# AST1080 register map
File version: 1.0
CPU: CM4 r0p1, little endian, MPU, FPU, 4 interrupt priority bits, 256 interrupts
Registers are 32-bit, read-write, reset 0x0 unless marked. A register's access mark holds for its fields unless they carry their own. Offsets are from the block's base; [hi:lo] are bit positions; {n}, {i} and the like mark numbered series.

## scu (part 2 of 2)
Base 0x74C02000
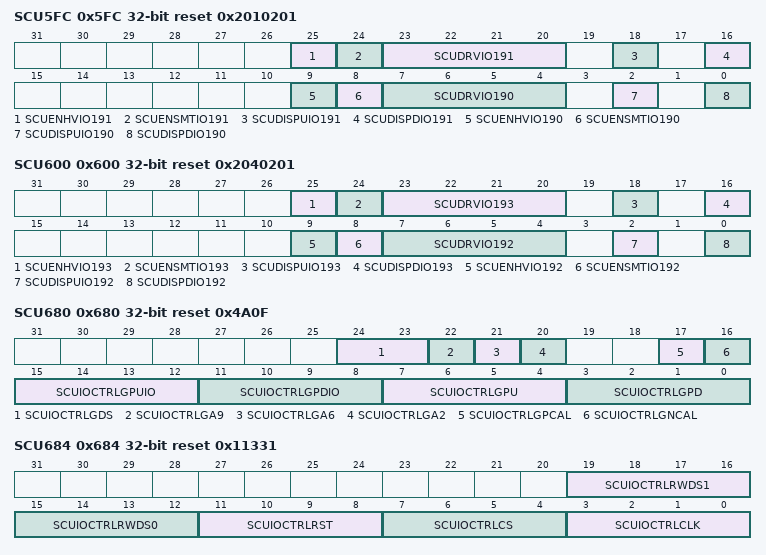
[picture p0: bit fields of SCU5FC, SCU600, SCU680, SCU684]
0x5FC SCU5FC reset 0x2010201 — IO Control \#96
  [25] SCUENHVIO191, [24] SCUENSMTIO191, [23:20] SCUDRVIO191, [18] SCUDISPUIO191, [16] SCUDISPDIO191, [9] SCUENHVIO190, [8] SCUENSMTIO190, [7:4] SCUDRVIO190, [2] SCUDISPUIO190, [0] SCUDISPDIO190
0x600 SCU600 reset 0x2040201 — IO Control \#97
  [25] SCUENHVIO193, [24] SCUENSMTIO193, [23:20] SCUDRVIO193, [18] SCUDISPUIO193, [16] SCUDISPDIO193, [9] SCUENHVIO192, [8] SCUENSMTIO192, [7:4] SCUDRVIO192, [2] SCUDISPUIO192, [0] SCUDISPDIO192
0x680 SCU680 reset 0x4A0F — IO Control 0 Regiser
  [24:23] SCUIOCTRLGDS, [22] SCUIOCTRLGA9, [21] SCUIOCTRLGA6, [20] SCUIOCTRLGA2, [17] SCUIOCTRLGPCAL, [16] SCUIOCTRLGNCAL, [15:12] SCUIOCTRLGPUIO, [11:8] SCUIOCTRLGPDIO, [7:4] SCUIOCTRLGPU, [3:0] SCUIOCTRLGPD
0x684 SCU684 reset 0x11331 — HRAM IO Control 1 Register
  [19:16] SCUIOCTRLRWDS1, [15:12] SCUIOCTRLRWDS0, [11:8] SCUIOCTRLRST, [7:4] SCUIOCTRLCS, [3:0] SCUIOCTRLCLK
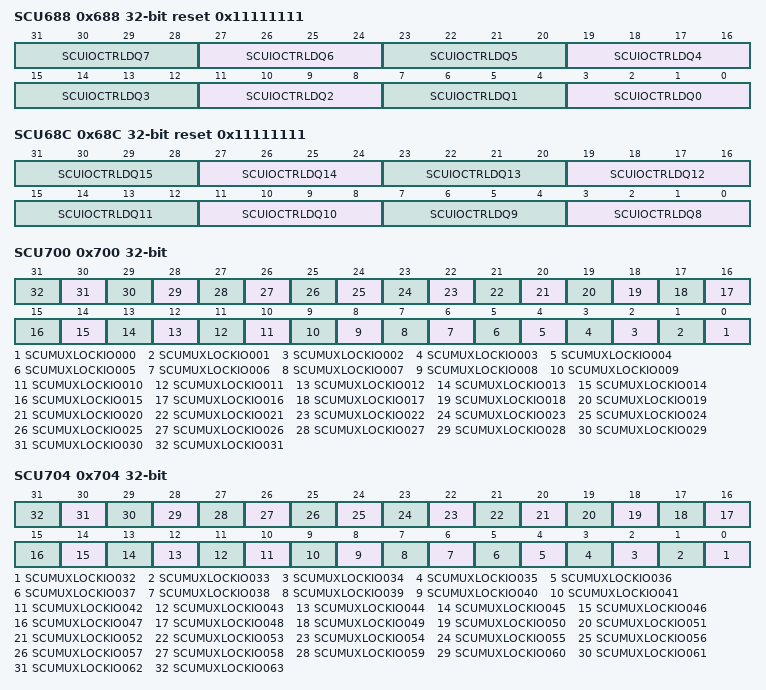
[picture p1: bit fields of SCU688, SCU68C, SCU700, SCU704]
0x688 SCU688 reset 0x11111111 — HRAM IO Control 2 Register
  [4n+3:4n] SCUIOCTRLDQ{n} (n=0..7)
0x68C SCU68C reset 0x11111111 — HRAM IO Control 3 Register
  [4n-29:4n-32] SCUIOCTRLDQ{n} (n=8..15)
0x6FC SCU6FC — GPIO Passthrough Debounce Register
  [3:0] SCUENGPIOPTDEB
0x700 SCU700 — IO Lock 1 Register 1
  [n] SCUMUXLOCKIO{n:03} (n=0..31)
0x704 SCU704 — IO Lock Register 2
  [n-32] SCUMUXLOCKIO{n:03} (n=32..63)
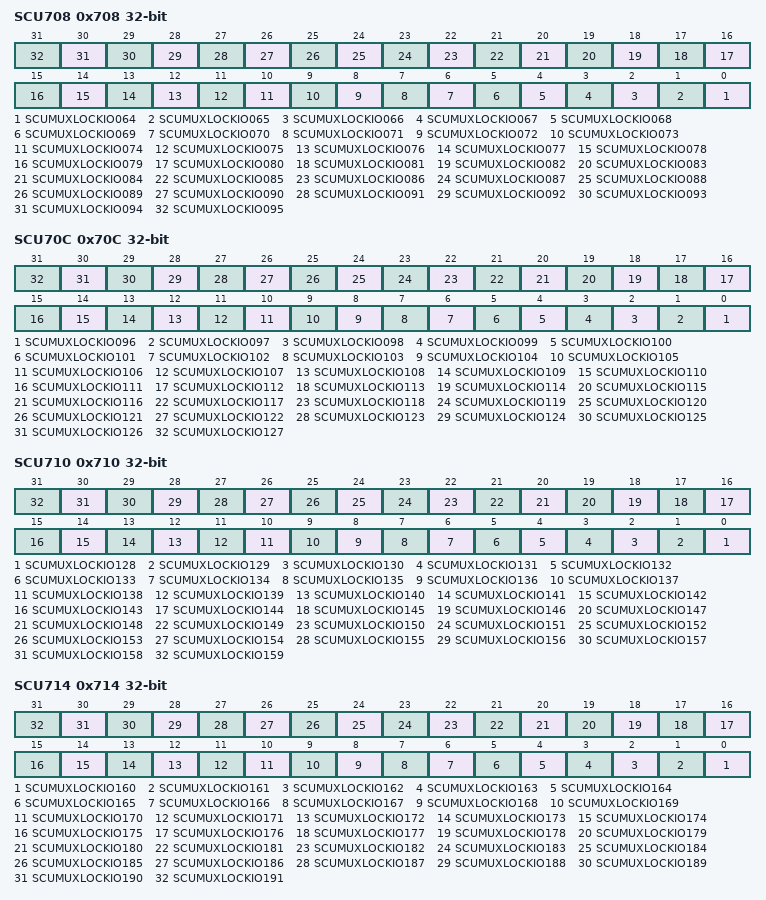
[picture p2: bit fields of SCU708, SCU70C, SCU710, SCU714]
0x708 SCU708 — IO Lock Register 3
  [n-64] SCUMUXLOCKIO{n:03} (n=64..95)
0x70C SCU70C — IO Lock Register 4
  [n-96] SCUMUXLOCKIO{n:03} (n=96..127)
0x710 SCU710 — IO Lock Register 5
  [n-128] SCUMUXLOCKIO{n} (n=128..159)
0x714 SCU714 — IO Lock Register 6
  [n-160] SCUMUXLOCKIO{n} (n=160..191)
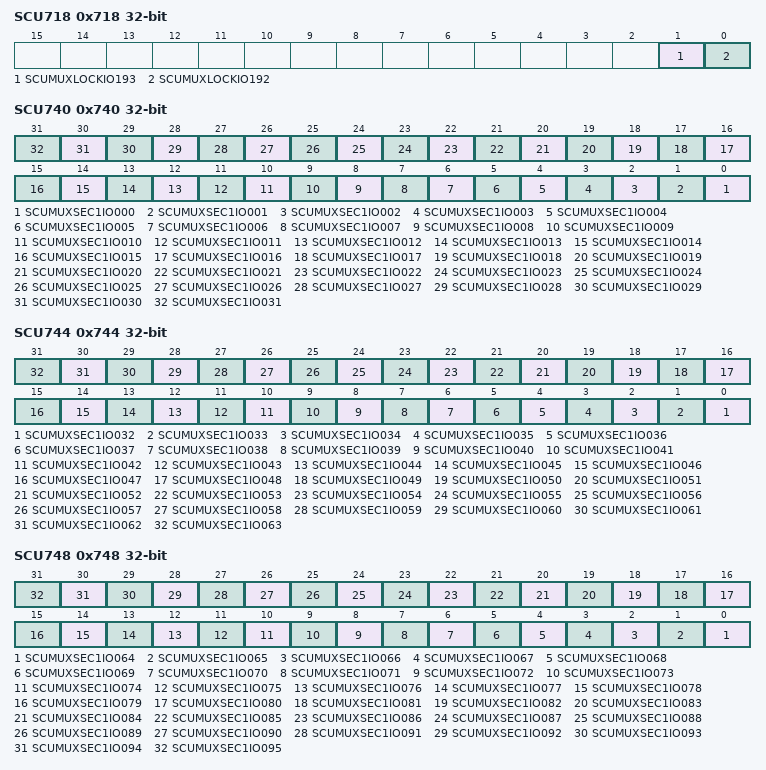
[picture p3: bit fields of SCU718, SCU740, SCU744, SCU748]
0x718 SCU718 — IO Lock Register 7
  [1] SCUMUXLOCKIO193, [0] SCUMUXLOCKIO192
0x740 SCU740 — IO Secure 1 Register 1
  [n] SCUMUXSEC1IO{n:03} (n=0..31)
0x744 SCU744 — IO Secure 1 Register 2
  [n-32] SCUMUXSEC1IO{n:03} (n=32..63)
0x748 SCU748 — IO Secure 1 Register 3
  [n-64] SCUMUXSEC1IO{n:03} (n=64..95)
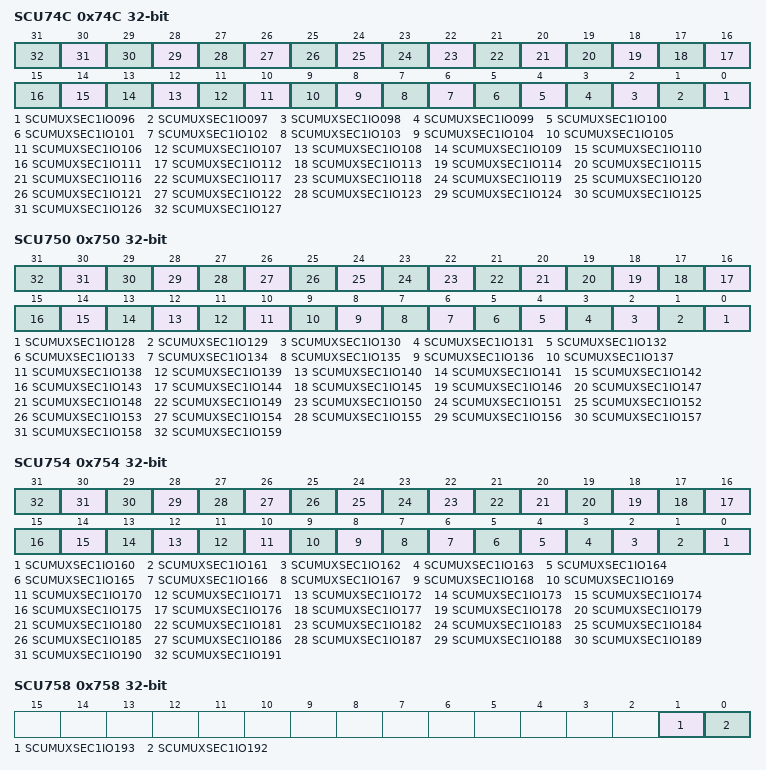
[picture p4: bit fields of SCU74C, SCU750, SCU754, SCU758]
0x74C SCU74C — IO Secure 1 Register 4
  [n-96] SCUMUXSEC1IO{n:03} (n=96..127)
0x750 SCU750 — IO Secure 1 Register 5
  [n-128] SCUMUXSEC1IO{n} (n=128..159)
0x754 SCU754 — IO Secure 1 Register 6
  [n-160] SCUMUXSEC1IO{n} (n=160..191)
0x758 SCU758 — IO Secure 1 Register 7
  [1] SCUMUXSEC1IO193, [0] SCUMUXSEC1IO192
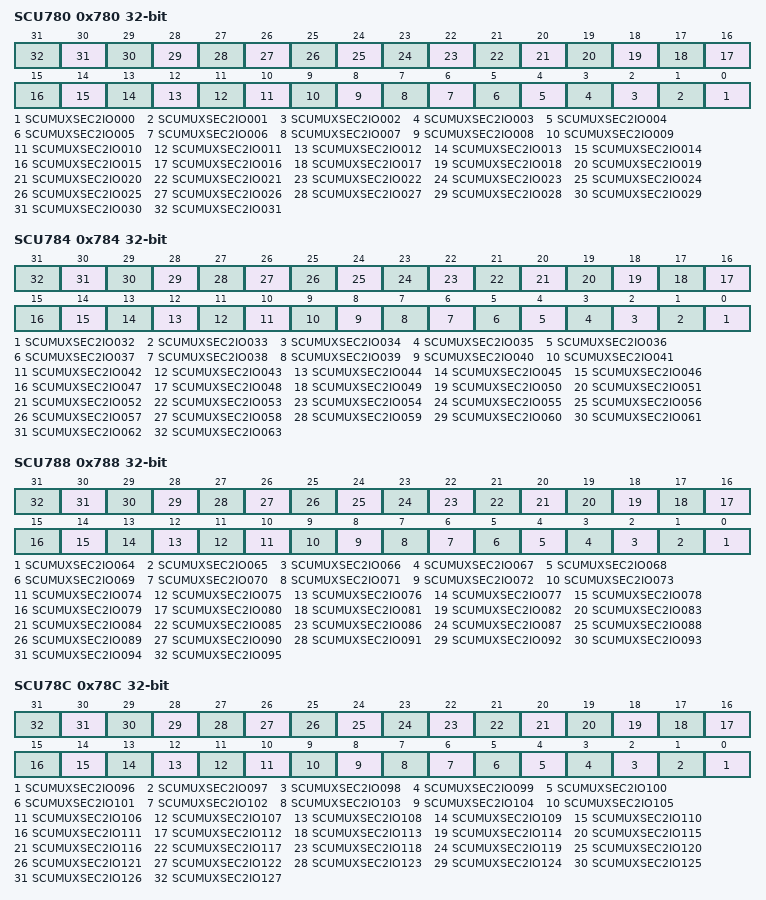
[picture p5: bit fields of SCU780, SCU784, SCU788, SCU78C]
0x780 SCU780 — IO SECURE 2 Register 1
  [n] SCUMUXSEC2IO{n:03} (n=0..31)
0x784 SCU784 — IO SECURE 2 Register 2
  [n-32] SCUMUXSEC2IO{n:03} (n=32..63)
0x788 SCU788 — IO SECURE 2 Register 3
  [n-64] SCUMUXSEC2IO{n:03} (n=64..95)
0x78C SCU78C — IO SECURE 2 Register 4
  [n-96] SCUMUXSEC2IO{n:03} (n=96..127)
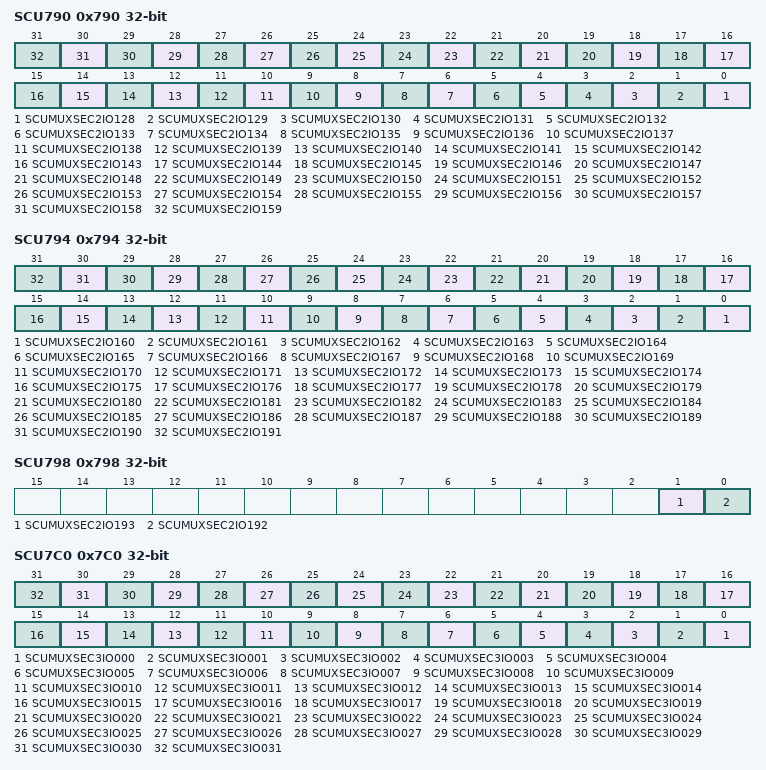
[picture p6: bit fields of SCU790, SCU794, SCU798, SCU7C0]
0x790 SCU790 — IO SECURE 2 Register 5
  [n-128] SCUMUXSEC2IO{n} (n=128..159)
0x794 SCU794 — IO SECURE 2 Register 6
  [n-160] SCUMUXSEC2IO{n} (n=160..191)
0x798 SCU798 — IO SECURE 2 Register 7
  [1] SCUMUXSEC2IO193, [0] SCUMUXSEC2IO192
0x7C0 SCU7C0 — IO Secure 3 Register 1
  [n] SCUMUXSEC3IO{n:03} (n=0..31)
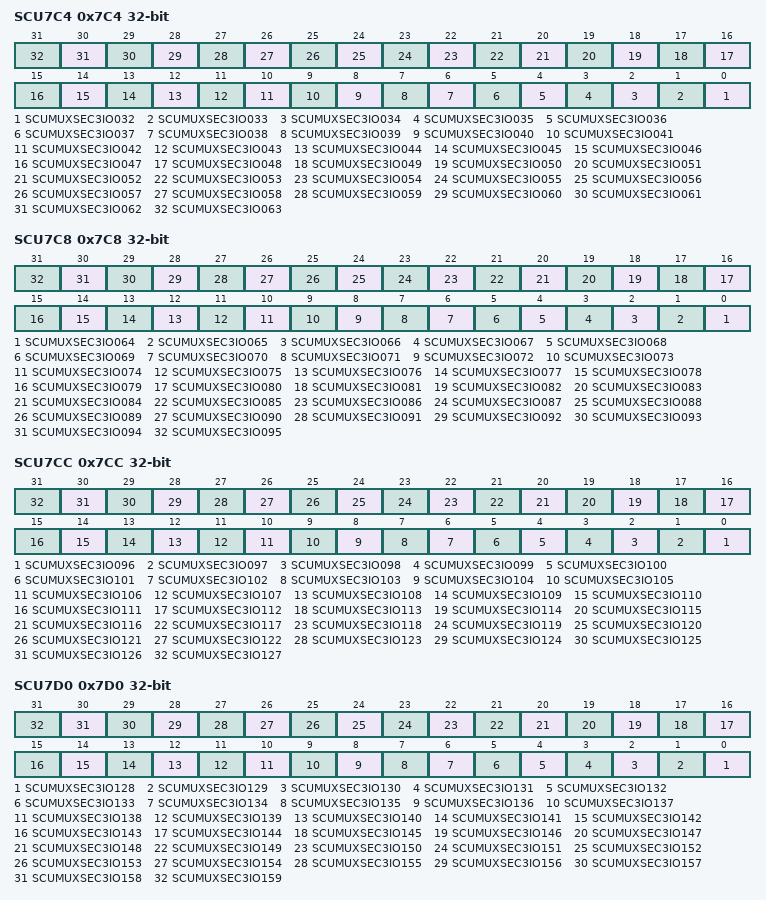
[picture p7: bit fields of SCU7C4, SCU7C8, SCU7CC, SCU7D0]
0x7C4 SCU7C4 — IO Secure 3 Register 2
  [n-32] SCUMUXSEC3IO{n:03} (n=32..63)
0x7C8 SCU7C8 — IO Secure 3 Register 3
  [n-64] SCUMUXSEC3IO{n:03} (n=64..95)
0x7CC SCU7CC — IO Secure 3 Register 4
  [n-96] SCUMUXSEC3IO{n:03} (n=96..127)
0x7D0 SCU7D0 — IO Secure 3 Register 5
  [n-128] SCUMUXSEC3IO{n} (n=128..159)
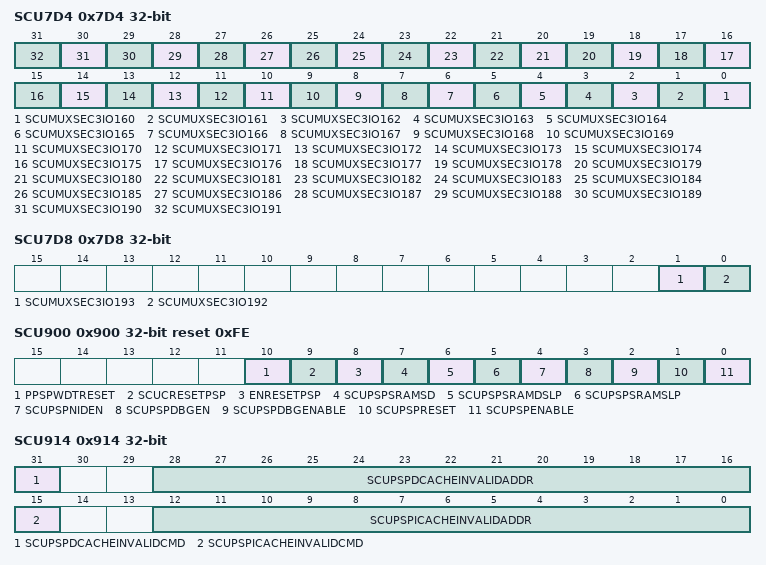
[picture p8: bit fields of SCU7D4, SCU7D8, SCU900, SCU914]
0x7D4 SCU7D4 — IO Secure 3 Register 6
  [n-160] SCUMUXSEC3IO{n} (n=160..191)
0x7D8 SCU7D8 — IO Secure 3 Register 7
  [1] SCUMUXSEC3IO193, [0] SCUMUXSEC3IO192
0x800 SCU800 — Scratch register for MCU 0
  [31:0] SCUSCRATCHMCU0
0x804 SCU804 — Scratch register for MCU 1
  [31:0] SCUSCRATCHMCU1
0x808 SCU808 — Scratch register for MCU 2
  [31:0] SCUSCRATCHMCU2
{0x30C+0x10*i} SCU{i}C (i=80..89) — Scratch register for MCU {4i-317}
  [31:0] SCUSCRATCHMCU{4i-317}
0x810 SCU810 — Scratch register for MCU 4
  [31:0] SCUSCRATCHMCU4
0x814 SCU814 — Scratch register for MCU 5
  [31:0] SCUSCRATCHMCU5
0x818 SCU818 — Scratch register for MCU 6
  [31:0] SCUSCRATCHMCU6
0x820 SCU820 — Scratch register for MCU 8
  [31:0] SCUSCRATCHMCU8
0x824 SCU824 — Scratch register for MCU 9
  [31:0] SCUSCRATCHMCU9
0x828 SCU828 — Scratch register for MCU 10
  [31:0] SCUSCRATCHMCU10
0x830 SCU830 — Scratch register for MCU 12
  [31:0] SCUSCRATCHMCU12
0x834 SCU834 — Scratch register for MCU 13
  [31:0] SCUSCRATCHMCU13
0x838 SCU838 — Scratch register for MCU 14
  [31:0] SCUSCRATCHMCU14
0x840 SCU840 — Scratch register for MCU 16
  [31:0] SCUSCRATCHMCU16
0x844 SCU844 — Scratch register for MCU 17
  [31:0] SCUSCRATCHMCU17
0x848 SCU848 — Scratch register for MCU 18
  [31:0] SCUSCRATCHMCU18
0x850 SCU850 — Scratch register for MCU 20
  [31:0] SCUSCRATCHMCU20
0x854 SCU854 — Scratch register for MCU 21
  [31:0] SCUSCRATCHMCU21
0x858 SCU858 — Scratch register for MCU 22
  [31:0] SCUSCRATCHMCU22
0x860 SCU860 — Scratch register for MCU 24
  [31:0] SCUSCRATCHMCU24
0x864 SCU864 — Scratch register for MCU 25
  [31:0] SCUSCRATCHMCU25
0x868 SCU868 — Scratch register for MCU 26
  [31:0] SCUSCRATCHMCU26
0x870 SCU870 — Scratch register for MCU 28
  [31:0] SCUSCRATCHMCU28
0x874 SCU874 — Scratch register for MCU 29
  [31:0] SCUSCRATCHMCU29
0x878 SCU878 — Scratch register for MCU 30
  [31:0] SCUSCRATCHMCU30
0x880 SCU880 — Scratch register for MCU 32
  [31:0] SCUSCRATCHMCU32
0x884 SCU884 — Scratch register for MCU 33
  [31:0] SCUSCRATCHMCU33
0x888 SCU888 — Scratch register for MCU 34
  [31:0] SCUSCRATCHMCU34
0x890 SCU890 — Scratch register for MCU 36
  [31:0] SCUSCRATCHMCU36
0x894 SCU894 — Scratch register for MCU 37
  [31:0] SCUSCRATCHMCU37
0x898 SCU898 — Scratch register for MCU 38
  [31:0] SCUSCRATCHMCU38
0x8A0 SCU8A0 — Scratch register for MCU 40
  [31:0] SCUSCRATCHMCU40
0x8A4 SCU8A4 — Scratch register for MCU 41
  [31:0] SCUSCRATCHMCU41
0x8A8 SCU8A8 — Scratch register for MCU 42
  [31:0] SCUSCRATCHMCU42
0x8AC SCU8AC — Scratch register for MCU 43
  [31:0] SCUSCRATCHMCU43
0x8B0 SCU8B0 — Scratch register for MCU 44
  [31:0] SCUSCRATCHMCU44
0x8B4 SCU8B4 — Scratch register for MCU 45
  [31:0] SCUSCRATCHMCU45
0x8B8 SCU8B8 — Scratch register for MCU 46
  [31:0] SCUSCRATCHMCU46
0x8BC SCU8BC — Scratch register for MCU 47
  [31:0] SCUSCRATCHMCU47
0x8C0 SCU8C0 — Scratch register for MCU 48
  [31:0] SCUSCRATCHMCU48
0x8C4 SCU8C4 — Scratch register for MCU 49
  [31:0] SCUSCRATCHMCU49
0x8C8 SCU8C8 — Scratch register for MCU 50
  [31:0] SCUSCRATCHMCU50
0x8CC SCU8CC — Scratch register for MCU 51
  [31:0] SCUSCRATCHMCU51
0x8D0 SCU8D0 — Scratch register for MCU 52
  [31:0] SCUSCRATCHMCU52
0x8D4 SCU8D4 — Scratch register for MCU 53
  [31:0] SCUSCRATCHMCU53
0x8D8 SCU8D8 — Scratch register for MCU 54
  [31:0] SCUSCRATCHMCU54
0x8DC SCU8DC — Scratch register for MCU 55
  [31:0] SCUSCRATCHMCU55
0x8E0 SCU8E0 — Scratch register for MCU 56
  [31:0] SCUSCRATCHMCU56
0x8E4 SCU8E4 — Scratch register for MCU 57
  [31:0] SCUSCRATCHMCU57
0x8E8 SCU8E8 — Scratch register for MCU 58
  [31:0] SCUSCRATCHMCU58
0x8EC SCU8EC — Scratch register for MCU 59
  [31:0] SCUSCRATCHMCU59
0x8F0 SCU8F0 — Scratch register for MCU 60
  [31:0] SCUSCRATCHMCU60
0x8F4 SCU8F4 — Scratch register for MCU 61
  [31:0] SCUSCRATCHMCU61
0x8F8 SCU8F8 — Scratch register for MCU 62
  [31:0] SCUSCRATCHMCU62
0x8FC SCU8FC — Scratch register for MCU 63
  [31:0] SCUSCRATCHMCU63
0x900 SCU900 reset 0xFE — \PSP\ Service Processor Control Register 1
  [10] PPSPWDTRESET ro, [9] SCUCRESETPSP ro, [8] ENRESETPSP ro, [7] SCUPSPSRAMSD, [6] SCUPSPSRAMDSLP, [5] SCUPSPSRAMSLP, [4] SCUPSPNIDEN, [3] SCUPSPDBGEN, [2] SCUPSPDBGENABLE, [1] SCUPSPRESET, [0] SCUPSPENABLE
0x904 SCU904 — \PSP\ Service Processor Control Register 2
  [31:0] SCUPSPREMAPAHBBASE
0x908 SCU908 — \PSP\ Service Processor Control Register 3
  [31:0] SCUPSPREMAPMEMBASE
0x90C SCU90C — \PSP\ Service Processor Control Register 4
  [31:0] SCUPSPICACHEABLE
0x910 SCU910 — \PSP\ Service Processor Control Register 5
  [31:0] SCUPSPDCACHEABLE
0x914 SCU914 — \PSP\ Service Processor Control Register 6
  [31] SCUPSPDCACHEINVALIDCMD, [28:16] SCUPSPDCACHEINVALIDADDR, [15] SCUPSPICACHEINVALIDCMD, [12:0] SCUPSPICACHEINVALIDADDR
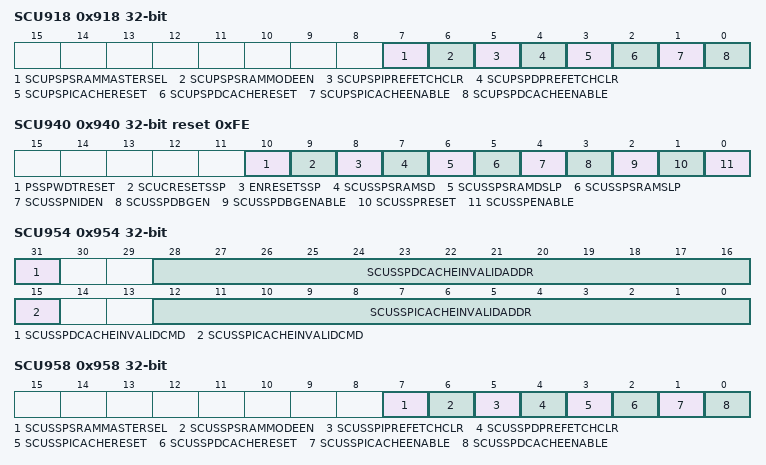
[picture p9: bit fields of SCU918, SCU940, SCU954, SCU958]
0x918 SCU918 — \PSP\ Service Processor Control Register 7
  [7] SCUPSPSRAMMASTERSEL, [6] SCUPSPSRAMMODEEN, [5] SCUPSPIPREFETCHCLR, [4] SCUPSPDPREFETCHCLR, [3] SCUPSPICACHERESET, [2] SCUPSPDCACHERESET, [1] SCUPSPICACHEENABLE, [0] SCUPSPDCACHEENABLE
0x920 SCU920 — \PSP\ Service Processor REMAP Base Register 0
  [29:0] SCUPSPMAPTCMSTART
0x924 SCU924 — \PSP\ Service Processor REMAP Size Register 0
  [29:0] SCUPSPMAPTCMSIZE
0x928 SCU928 — \PSP\ Service Processor REMAP Base Register 1
  [29:0] SCUPSPMAPAHBSTART
0x92C SCU92C — \PSP\ Service Processor REMAP Size Register 1
  [29:0] SCUPSPMAPAHBSIZE
0x930 SCU930 — \PSP\ Service Processor REMAP Base Register 2
  [29:0] SCUPSPMAPMEMSTART
0x934 SCU934 — \PSP\ Service Processor REMAP Size Register 2
  [29:0] SCUPSPMAPMEMSIZE
0x940 SCU940 reset 0xFE — \SSP\ Service Processor Control Register
  [10] PSSPWDTRESET ro, [9] SCUCRESETSSP ro, [8] ENRESETSSP ro, [7] SCUSSPSRAMSD, [6] SCUSSPSRAMDSLP, [5] SCUSSPSRAMSLP, [4] SCUSSPNIDEN, [3] SCUSSPDBGEN, [2] SCUSSPDBGENABLE, [1] SCUSSPRESET, [0] SCUSSPENABLE
0x948 SCU948 reset 0x10000000 — \SSP\ Service Processor Control Register 3
  [31:0] SCUSSPREMAPMEMBASE
0x94C SCU94C — \SSP\ Service Processor Control Register 4
  [31:0] SCUSSPICACHEABLE
0x950 SCU950 — \SSP\ Service Processor Control Register 5
  [31:0] SCUSSPDCACHEABLE
0x954 SCU954 — \SSP\ Service Processor Control Register 6
  [31] SCUSSPDCACHEINVALIDCMD, [28:16] SCUSSPDCACHEINVALIDADDR, [15] SCUSSPICACHEINVALIDCMD, [12:0] SCUSSPICACHEINVALIDADDR
0x958 SCU958 — \SSP\ Service Processor Control Register 7
  [7] SCUSSPSRAMMASTERSEL, [6] SCUSSPSRAMMODEEN, [5] SCUSSPIPREFETCHCLR, [4] SCUSSPDPREFETCHCLR, [3] SCUSSPICACHERESET, [2] SCUSSPDCACHERESET, [1] SCUSSPICACHEENABLE, [0] SCUSSPDCACHEENABLE
0x974 SCU974 reset 0x100000 — \SSP\ Service Processor REMAP Size Register 2
  [29:0] SCUSSPMAPMEMSIZE
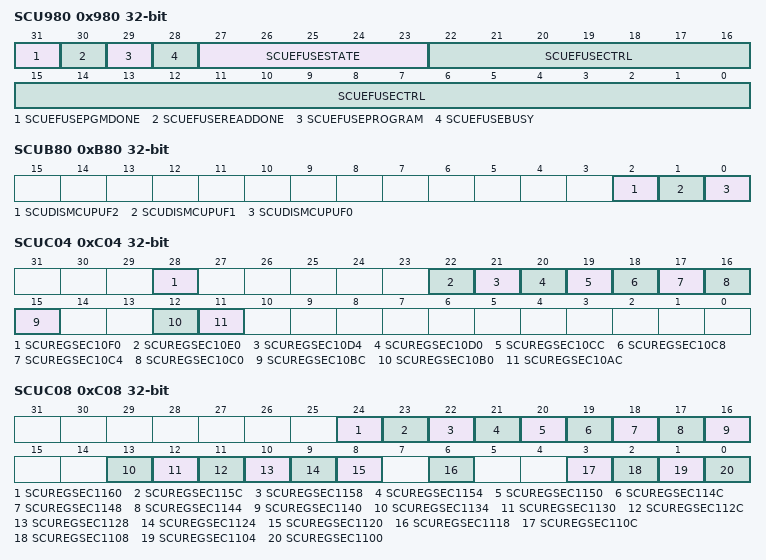
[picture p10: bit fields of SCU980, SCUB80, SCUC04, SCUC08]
0x980 SCU980 — EFUSE Control Register
  [31] SCUEFUSEPGMDONE ro, [30] SCUEFUSEREADDONE ro, [29] SCUEFUSEPROGRAM ro, [28] SCUEFUSEBUSY ro, [27:23] SCUEFUSESTATE ro, [22:0] SCUEFUSECTRL
0x984 SCU984 — EFUSE Data Register
  [31:0] SCUEFUSEDATA ro
0x988 SCU988 — EFUSE Command Register
  [31:0] SCUEFUSECMD ro
0x98C SCU98C — EFUSE Program Pattern Register
  [31:0] SCUEFUSEPTN
0x990 SCU990 — Chip Unique ID 0
  [31:0] SCUEFUSECHIPID0 ro
0x994 SCU994 — Chip Unique ID 1
  [31:0] SCUEFUSECHIPID1 ro
0x998 SCU998 — Reserved Read Only ID 0
  [31:0] SCUEFUSERSVDID0 ro
0x99C SCU99C — Reserved Read Only ID 1
  [31:0] SCUEFUSERSVDID1 ro
0x9A0 SCU9A0 — Reserved Read Only ID 2
  [31:0] SCUEFUSERSVDID2 ro
0x9A4 SCU9A4 — Reserved Read Only ID 3
  [31:0] SCUEFUSERSVDID3 ro
0x9A8 SCU9A8 — Reserved Read Only ID 4
  [31:0] SCUEFUSERSVDID4 ro
0x9AC SCU9AC — Reserved Read Only ID 5
  [31:0] SCUEFUSERSVDID5 ro
0x9B0 SCU9B0 reset 0x1411218 — EFUSE PGM Timing Register 0
  [31:0] SCUEFUSEPGMTIMING0
0x9B4 SCU9B4 reset 0x2211 — EFUSE PGM Timing Register 1
  [31:0] SCUEFUSEPGMTIMING1
0x9B8 SCU9B8 reset 0x411218 — EFUSE Read Timing Register 0
  [31:0] SCUEFUSEREADTIMING0
0x9BC SCU9BC reset 0x2211 — EFUSE Read Timing Register 1
  [31:0] SCUEFUSEREADTIMING1
0xB00 SCUB00 — SW PUF Register 0
  [31:0] SCUSWPUF0 ro
0xB04 SCUB04 — SW PUF Register 1
  [31:0] SCUSWPUF1 ro
0xB08 SCUB08 — SW PUF Register 2
  [31:0] SCUSWPUF2 ro
{0xB0C+0x10*i} SCUB{i}C (i=0..7) — SW PUF Register {4i+3}
  [31:0] SCUSWPUF{4i+3} ro
0xB10 SCUB10 — SW PUF Register 4
  [31:0] SCUSWPUF4 ro
0xB14 SCUB14 — SW PUF Register 5
  [31:0] SCUSWPUF5 ro
0xB18 SCUB18 — SW PUF Register 6
  [31:0] SCUSWPUF6 ro
0xB20 SCUB20 — SW PUF Register 8
  [31:0] SCUSWPUF8 ro
0xB24 SCUB24 — SW PUF Register 9
  [31:0] SCUSWPUF9 ro
0xB28 SCUB28 — SW PUF Register 10
  [31:0] SCUSWPUF10 ro
0xB30 SCUB30 — SW PUF Register 12
  [31:0] SCUSWPUF12 ro
0xB34 SCUB34 — SW PUF Register 13
  [31:0] SCUSWPUF13 ro
0xB38 SCUB38 — SW PUF Register 14
  [31:0] SCUSWPUF14 ro
0xB40 SCUB40 — SW PUF Register 16
  [31:0] SCUSWPUF16 ro
0xB44 SCUB44 — SW PUF Register 17
  [31:0] SCUSWPUF17 ro
0xB48 SCUB48 — SW PUF Register 18
  [31:0] SCUSWPUF18 ro
0xB50 SCUB50 — SW PUF Register 20
  [31:0] SCUSWPUF20 ro
0xB54 SCUB54 — SW PUF Register 21
  [31:0] SCUSWPUF21 ro
0xB58 SCUB58 — SW PUF Register 22
  [31:0] SCUSWPUF22 ro
0xB60 SCUB60 — SW PUF Register 24
  [31:0] SCUSWPUF24 ro
0xB64 SCUB64 — SW PUF Register 25
  [31:0] SCUSWPUF25 ro
0xB68 SCUB68 — SW PUF Register 26
  [31:0] SCUSWPUF26 ro
0xB70 SCUB70 — SW PUF Register 28
  [31:0] SCUSWPUF28 ro
0xB74 SCUB74 — SW PUF Register 29
  [31:0] SCUSWPUF29 ro
0xB78 SCUB78 — SW PUF Register 30
  [31:0] SCUSWPUF30 ro
0xB80 SCUB80 — PUF Control Register
  [2] SCUDISMCUPUF2, [1] SCUDISMCUPUF1, [0] SCUDISMCUPUF0
0xBA0 SCUBA0 — HW PUF Register 8
  [31:0] SCUHWPUF8 ro
0xBA4 SCUBA4 — HW PUF Register 9
  [31:0] SCUHWPUF9 ro
0xBA8 SCUBA8 — HW PUF Register 10
  [31:0] SCUHWPUF10 ro
0xBAC SCUBAC — HW PUF Register 11
  [31:0] SCUHWPUF11 ro
0xBB0 SCUBB0 — HW PUF Register 12
  [31:0] SCUHWPUF12 ro
0xBB4 SCUBB4 — HW PUF Register 13
  [31:0] SCUHWPUF13 ro
0xBB8 SCUBB8 — HW PUF Register 14
  [31:0] SCUHWPUF14 ro
0xBBC SCUBBC — HW PUF Register 15
  [31:0] SCUHWPUF15 ro
0xBC0 SCUBC0 — HW PUF Register 16
  [31:0] SCUHWPUF16 ro
0xBC4 SCUBC4 — HW PUF Register 17
  [31:0] SCUHWPUF17 ro
0xBC8 SCUBC8 — HW PUF Register 18
  [31:0] SCUHWPUF18 ro
0xBCC SCUBCC — HW PUF Register 19
  [31:0] SCUHWPUF19 ro
0xBD0 SCUBD0 — HW PUF Register 20
  [31:0] SCUHWPUF20 ro
0xBD4 SCUBD4 — HW PUF Register 21
  [31:0] SCUHWPUF21 ro
0xBD8 SCUBD8 — HW PUF Register 22
  [31:0] SCUHWPUF22 ro
0xBDC SCUBDC — HW PUF Register 23
  [31:0] SCUHWPUF23 ro
0xBE0 SCUBE0 — HW PUF Register 24
  [31:0] SCUHWPUF24 ro
0xBE4 SCUBE4 — HW PUF Register 25
  [31:0] SCUHWPUF25 ro
0xBE8 SCUBE8 — HW PUF Register 26
  [31:0] SCUHWPUF26 ro
0xBEC SCUBEC — HW PUF Register 27
  [31:0] SCUHWPUF27 ro
0xBF0 SCUBF0 — HW PUF Register 28
  [31:0] SCUHWPUF28 ro
0xBF4 SCUBF4 — HW PUF Register 29
  [31:0] SCUHWPUF29 ro
0xBF8 SCUBF8 — HW PUF Register 30
  [31:0] SCUHWPUF30 ro
0xBFC SCUBFC — HW PUF Register 31
  [31:0] SCUHWPUF31 ro
0xC04 SCUC04 — Secure1 Control 2 Register
  [28] SCUREGSEC10F0, [22] SCUREGSEC10E0, [21] SCUREGSEC10D4, [20] SCUREGSEC10D0, [19] SCUREGSEC10CC, [18] SCUREGSEC10C8, [17] SCUREGSEC10C4, [16] SCUREGSEC10C0, [15] SCUREGSEC10BC, [12] SCUREGSEC10B0, [11] SCUREGSEC10AC
0xC08 SCUC08 — Secure1 Control 3 Register
  [24] SCUREGSEC1160, [23] SCUREGSEC115C, [22] SCUREGSEC1158, [21] SCUREGSEC1154, [20] SCUREGSEC1150, [19] SCUREGSEC114C, [18] SCUREGSEC1148, [17] SCUREGSEC1144, [16] SCUREGSEC1140, [13] SCUREGSEC1134, [12] SCUREGSEC1130, [11] SCUREGSEC112C, [10] SCUREGSEC1128, [9] SCUREGSEC1124, [8] SCUREGSEC1120, [6] SCUREGSEC1118, [3] SCUREGSEC110C, [2] SCUREGSEC1108, [1] SCUREGSEC1104, [0] SCUREGSEC1100
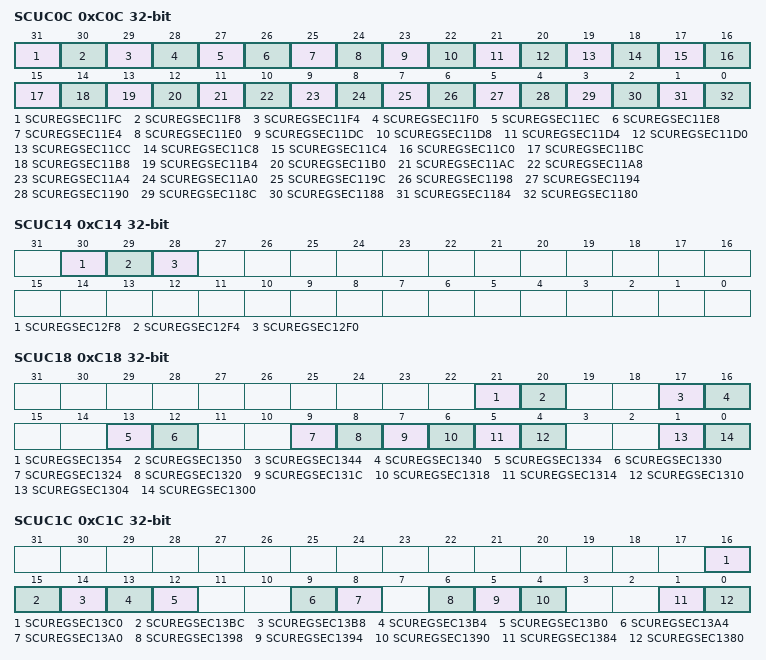
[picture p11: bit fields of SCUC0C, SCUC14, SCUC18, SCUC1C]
0xC0C SCUC0C — Secure1 Control 4 Register
  [31] SCUREGSEC11FC, [30] SCUREGSEC11F8, [29] SCUREGSEC11F4, [28] SCUREGSEC11F0, [27] SCUREGSEC11EC, [26] SCUREGSEC11E8, [25] SCUREGSEC11E4, [24] SCUREGSEC11E0, [23] SCUREGSEC11DC, [22] SCUREGSEC11D8, [21] SCUREGSEC11D4, [20] SCUREGSEC11D0, [19] SCUREGSEC11CC, [18] SCUREGSEC11C8, [17] SCUREGSEC11C4, [16] SCUREGSEC11C0, [15] SCUREGSEC11BC, [14] SCUREGSEC11B8, [13] SCUREGSEC11B4, [12] SCUREGSEC11B0, [11] SCUREGSEC11AC, [10] SCUREGSEC11A8, [9] SCUREGSEC11A4, [8] SCUREGSEC11A0, [7] SCUREGSEC119C, [6] SCUREGSEC1198, [5] SCUREGSEC1194, [4] SCUREGSEC1190, [3] SCUREGSEC118C, [2] SCUREGSEC1188, [1] SCUREGSEC1184, [0] SCUREGSEC1180
0xC14 SCUC14 — Secure1 Control 6 Register
  [30] SCUREGSEC12F8, [29] SCUREGSEC12F4, [28] SCUREGSEC12F0
0xC18 SCUC18 — Secure1 Control 7 Register
  [21] SCUREGSEC1354, [20] SCUREGSEC1350, [17] SCUREGSEC1344, [16] SCUREGSEC1340, [13] SCUREGSEC1334, [12] SCUREGSEC1330, [9] SCUREGSEC1324, [8] SCUREGSEC1320, [7] SCUREGSEC131C, [6] SCUREGSEC1318, [5] SCUREGSEC1314, [4] SCUREGSEC1310, [1] SCUREGSEC1304, [0] SCUREGSEC1300
0xC1C SCUC1C — Secure1 Control 8 Register
  [16] SCUREGSEC13C0, [15] SCUREGSEC13BC, [14] SCUREGSEC13B8, [13] SCUREGSEC13B4, [12] SCUREGSEC13B0, [9] SCUREGSEC13A4, [8] SCUREGSEC13A0, [6] SCUREGSEC1398, [5] SCUREGSEC1394, [4] SCUREGSEC1390, [1] SCUREGSEC1384, [0] SCUREGSEC1380
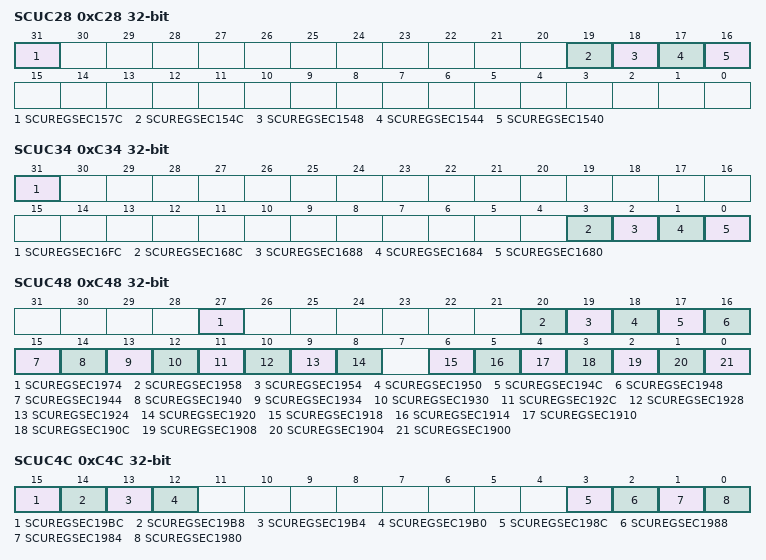
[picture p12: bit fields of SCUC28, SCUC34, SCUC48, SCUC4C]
0xC28 SCUC28 — Secure1 Control 11 Register
  [31] SCUREGSEC157C, [19] SCUREGSEC154C, [18] SCUREGSEC1548, [17] SCUREGSEC1544, [16] SCUREGSEC1540
0xC34 SCUC34 — Secure1 Control 14 Register
  [31] SCUREGSEC16FC, [3] SCUREGSEC168C, [2] SCUREGSEC1688, [1] SCUREGSEC1684, [0] SCUREGSEC1680
0xC48 SCUC48 — Secure1 Control 19 Register
  [27] SCUREGSEC1974, [20] SCUREGSEC1958, [19] SCUREGSEC1954, [18] SCUREGSEC1950, [17] SCUREGSEC194C, [16] SCUREGSEC1948, [15] SCUREGSEC1944, [14] SCUREGSEC1940, [13] SCUREGSEC1934, [12] SCUREGSEC1930, [11] SCUREGSEC192C, [10] SCUREGSEC1928, [9] SCUREGSEC1924, [8] SCUREGSEC1920, [6] SCUREGSEC1918, [5] SCUREGSEC1914, [4] SCUREGSEC1910, [3] SCUREGSEC190C, [2] SCUREGSEC1908, [1] SCUREGSEC1904, [0] SCUREGSEC1900
0xC4C SCUC4C — Secure1 Control 20 Register
  [15] SCUREGSEC19BC, [14] SCUREGSEC19B8, [13] SCUREGSEC19B4, [12] SCUREGSEC19B0, [3] SCUREGSEC198C, [2] SCUREGSEC1988, [1] SCUREGSEC1984, [0] SCUREGSEC1980
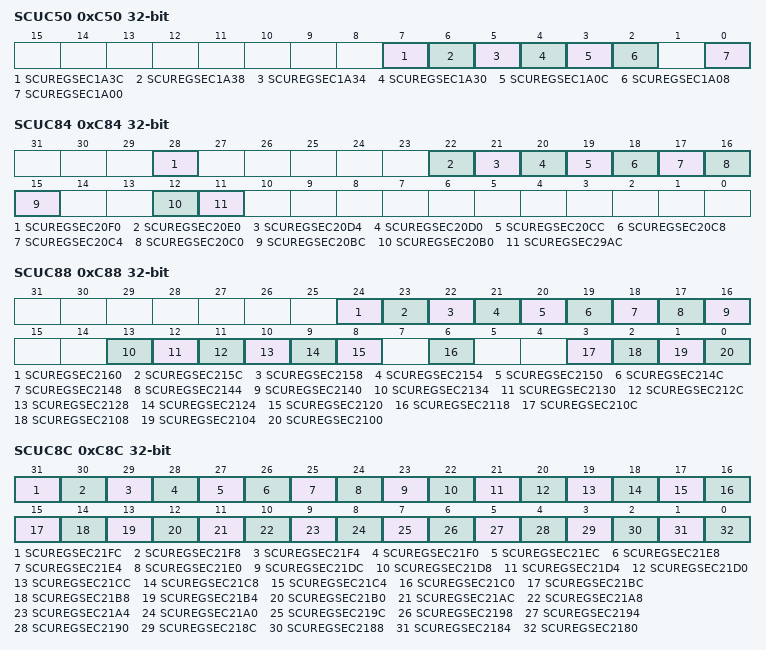
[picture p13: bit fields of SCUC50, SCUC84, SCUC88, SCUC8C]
0xC50 SCUC50 — Secure1 Control 21 Register
  [7] SCUREGSEC1A3C, [6] SCUREGSEC1A38, [5] SCUREGSEC1A34, [4] SCUREGSEC1A30, [3] SCUREGSEC1A0C, [2] SCUREGSEC1A08, [0] SCUREGSEC1A00
0xC5C SCUC5C — Secure1 Control 24 Register
  [0] SCUREGSEC1B80
0xC84 SCUC84 — Secure2 Control 2 Register
  [28] SCUREGSEC20F0, [22] SCUREGSEC20E0, [21] SCUREGSEC20D4, [20] SCUREGSEC20D0, [19] SCUREGSEC20CC, [18] SCUREGSEC20C8, [17] SCUREGSEC20C4, [16] SCUREGSEC20C0, [15] SCUREGSEC20BC, [12] SCUREGSEC20B0, [11] SCUREGSEC29AC
0xC88 SCUC88 — Secure2 Control 3 Register
  [24] SCUREGSEC2160, [23] SCUREGSEC215C, [22] SCUREGSEC2158, [21] SCUREGSEC2154, [20] SCUREGSEC2150, [19] SCUREGSEC214C, [18] SCUREGSEC2148, [17] SCUREGSEC2144, [16] SCUREGSEC2140, [13] SCUREGSEC2134, [12] SCUREGSEC2130, [11] SCUREGSEC212C, [10] SCUREGSEC2128, [9] SCUREGSEC2124, [8] SCUREGSEC2120, [6] SCUREGSEC2118, [3] SCUREGSEC210C, [2] SCUREGSEC2108, [1] SCUREGSEC2104, [0] SCUREGSEC2100
0xC8C SCUC8C — Secure2 Control 4 Register
  [31] SCUREGSEC21FC, [30] SCUREGSEC21F8, [29] SCUREGSEC21F4, [28] SCUREGSEC21F0, [27] SCUREGSEC21EC, [26] SCUREGSEC21E8, [25] SCUREGSEC21E4, [24] SCUREGSEC21E0, [23] SCUREGSEC21DC, [22] SCUREGSEC21D8, [21] SCUREGSEC21D4, [20] SCUREGSEC21D0, [19] SCUREGSEC21CC, [18] SCUREGSEC21C8, [17] SCUREGSEC21C4, [16] SCUREGSEC21C0, [15] SCUREGSEC21BC, [14] SCUREGSEC21B8, [13] SCUREGSEC21B4, [12] SCUREGSEC21B0, [11] SCUREGSEC21AC, [10] SCUREGSEC21A8, [9] SCUREGSEC21A4, [8] SCUREGSEC21A0, [7] SCUREGSEC219C, [6] SCUREGSEC2198, [5] SCUREGSEC2194, [4] SCUREGSEC2190, [3] SCUREGSEC218C, [2] SCUREGSEC2188, [1] SCUREGSEC2184, [0] SCUREGSEC2180
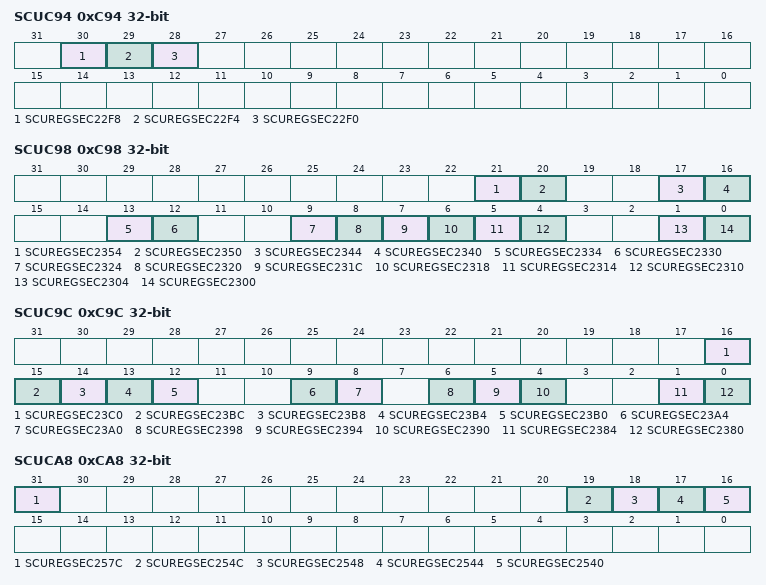
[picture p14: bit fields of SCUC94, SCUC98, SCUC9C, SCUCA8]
0xC94 SCUC94 — Secure2 Control 6 Register
  [30] SCUREGSEC22F8, [29] SCUREGSEC22F4, [28] SCUREGSEC22F0
0xC98 SCUC98 — Secure2 Control 7 Register
  [21] SCUREGSEC2354, [20] SCUREGSEC2350, [17] SCUREGSEC2344, [16] SCUREGSEC2340, [13] SCUREGSEC2334, [12] SCUREGSEC2330, [9] SCUREGSEC2324, [8] SCUREGSEC2320, [7] SCUREGSEC231C, [6] SCUREGSEC2318, [5] SCUREGSEC2314, [4] SCUREGSEC2310, [1] SCUREGSEC2304, [0] SCUREGSEC2300
0xC9C SCUC9C — Secure2 Control 7 Register
  [16] SCUREGSEC23C0, [15] SCUREGSEC23BC, [14] SCUREGSEC23B8, [13] SCUREGSEC23B4, [12] SCUREGSEC23B0, [9] SCUREGSEC23A4, [8] SCUREGSEC23A0, [6] SCUREGSEC2398, [5] SCUREGSEC2394, [4] SCUREGSEC2390, [1] SCUREGSEC2384, [0] SCUREGSEC2380
0xCA8 SCUCA8 — Secure2 Control 11 Register
  [31] SCUREGSEC257C, [19] SCUREGSEC254C, [18] SCUREGSEC2548, [17] SCUREGSEC2544, [16] SCUREGSEC2540
0xCB4 SCUCB4 — Secure2 Control 14 Register
  [31] SCUREGSEC26FC, [3] SCUREGSEC268C, [2] SCUREGSEC2688, [1] SCUREGSEC2684, [0] SCUREGSEC2680
0xCC8 SCUCC8 — Secure2 Control 19 Register
  [27] SCUREGSEC2974, [20] SCUREGSEC2958, [19] SCUREGSEC2954, [18] SCUREGSEC2950, [17] SCUREGSEC294C, [16] SCUREGSEC2948, [15] SCUREGSEC2944, [14] SCUREGSEC2940, [13] SCUREGSEC2934, [12] SCUREGSEC2930, [11] SCUREGSEC292C, [10] SCUREGSEC2928, [9] SCUREGSEC2924, [8] SCUREGSEC2920, [6] SCUREGSEC2918, [5] SCUREGSEC2914, [4] SCUREGSEC2910, [3] SCUREGSEC290C, [2] SCUREGSEC2908, [1] SCUREGSEC2904, [0] SCUREGSEC2900
0xCCC SCUCCC — Secure2 Control 20 Register
  [15] SCUREGSEC29BC, [14] SCUREGSEC29B8, [13] SCUREGSEC29B4, [12] SCUREGSEC29B0, [3] SCUREGSEC298C, [2] SCUREGSEC2988, [1] SCUREGSEC2984, [0] SCUREGSEC2980
0xCD0 SCUCD0 — Secure2 Control 21 Register
  [7] SCUREGSEC2A3C, [6] SCUREGSEC2A38, [5] SCUREGSEC2A34, [4] SCUREGSEC2A30, [3] SCUREGSEC2A0C, [2] SCUREGSEC2A08, [0] SCUREGSEC2A00
0xCDC SCUCDC — Secure2 Control 24 Register
  [0] SCUREGSEC2B80
0xD04 SCUD04 — Secure3 Control 2 Register
  [28] SCUREGSEC30F0, [22] SCUREGSEC30E0, [21] SCUREGSEC30D4, [20] SCUREGSEC30D0, [19] SCUREGSEC30CC, [18] SCUREGSEC30C8, [17] SCUREGSEC30C4, [16] SCUREGSEC30C0, [15] SCUREGSEC30BC, [12] SCUREGSEC30B0, [11] SCUREGSEC39AC
0xD08 SCUD08 — Secure3 Control 3 Register
  [24] SCUREGSEC3160, [23] SCUREGSEC315C, [22] SCUREGSEC3158, [21] SCUREGSEC3154, [20] SCUREGSEC3150, [19] SCUREGSEC314C, [18] SCUREGSEC3148, [17] SCUREGSEC3144, [16] SCUREGSEC3140, [13] SCUREGSEC3134, [12] SCUREGSEC3130, [11] SCUREGSEC312C, [10] SCUREGSEC3128, [9] SCUREGSEC3124, [8] SCUREGSEC3120, [6] SCUREGSEC3118, [3] SCUREGSEC310C, [2] SCUREGSEC3108, [1] SCUREGSEC3104, [0] SCUREGSEC3100
0xD0C SCUD0C — Secure3 Control 4 Register
  [31] SCUREGSEC31FC, [30] SCUREGSEC31F8, [29] SCUREGSEC31F4, [28] SCUREGSEC31F0, [27] SCUREGSEC31EC, [26] SCUREGSEC31E8, [25] SCUREGSEC31E4, [24] SCUREGSEC31E0, [23] SCUREGSEC31DC, [22] SCUREGSEC31D8, [21] SCUREGSEC31D4, [20] SCUREGSEC31D0, [19] SCUREGSEC31CC, [18] SCUREGSEC31C8, [17] SCUREGSEC31C4, [16] SCUREGSEC31C0, [15] SCUREGSEC31BC, [14] SCUREGSEC31B8, [13] SCUREGSEC31B4, [12] SCUREGSEC31B0, [11] SCUREGSEC31AC, [10] SCUREGSEC31A8, [9] SCUREGSEC31A4, [8] SCUREGSEC31A0, [7] SCUREGSEC319C, [6] SCUREGSEC3198, [5] SCUREGSEC3194, [4] SCUREGSEC3190, [3] SCUREGSEC318C, [2] SCUREGSEC3188, [1] SCUREGSEC3184, [0] SCUREGSEC3180
0xD14 SCUD14 — Secure3 Control 6 Register
  [30] SCUREGSEC32F8, [29] SCUREGSEC32F4, [28] SCUREGSEC32F0
0xD18 SCUD18 — Secure3 Control 7 Register
  [21] SCUREGSEC3354, [20] SCUREGSEC3350, [17] SCUREGSEC3344, [16] SCUREGSEC3340, [13] SCUREGSEC3334, [12] SCUREGSEC3330, [9] SCUREGSEC3324, [8] SCUREGSEC3320, [7] SCUREGSEC331C, [6] SCUREGSEC3318, [5] SCUREGSEC3314, [4] SCUREGSEC3310, [1] SCUREGSEC3304, [0] SCUREGSEC3300
0xD1C SCUD1C — Secure3 Control 7 Register
  [16] SCUREGSEC33C0, [15] SCUREGSEC33BC, [14] SCUREGSEC33B8, [13] SCUREGSEC33B4, [12] SCUREGSEC33B0, [9] SCUREGSEC33A4, [8] SCUREGSEC33A0, [6] SCUREGSEC3398, [5] SCUREGSEC3394, [4] SCUREGSEC3390, [1] SCUREGSEC3384, [0] SCUREGSEC3380
0xD28 SCUD28 — Secure3 Control 11 Register
  [31] SCUREGSEC357C, [19] SCUREGSEC354C, [18] SCUREGSEC3548, [17] SCUREGSEC3544, [16] SCUREGSEC3540
0xD34 SCUD34 — Secure3 Control 14 Register
  [31] SCUREGSEC36FC, [3] SCUREGSEC368C, [2] SCUREGSEC3688, [1] SCUREGSEC3684, [0] SCUREGSEC3680
0xD48 SCUD48 — Secure3 Control 19 Register
  [27] SCUREGSEC3974, [20] SCUREGSEC3958, [19] SCUREGSEC3954, [18] SCUREGSEC3950, [17] SCUREGSEC394C, [16] SCUREGSEC3948, [15] SCUREGSEC3944, [14] SCUREGSEC3940, [13] SCUREGSEC3934, [12] SCUREGSEC3930, [11] SCUREGSEC392C, [10] SCUREGSEC3928, [9] SCUREGSEC3924, [8] SCUREGSEC3920, [6] SCUREGSEC3918, [5] SCUREGSEC3914, [4] SCUREGSEC3910, [3] SCUREGSEC390C, [2] SCUREGSEC3908, [1] SCUREGSEC3904, [0] SCUREGSEC3900
0xD4C SCUD4C — Secure3 Control 20 Register
  [15] SCUREGSEC39BC, [14] SCUREGSEC39B8, [13] SCUREGSEC39B4, [12] SCUREGSEC39B0, [3] SCUREGSEC398C, [2] SCUREGSEC3988, [1] SCUREGSEC3984, [0] SCUREGSEC3980
0xD50 SCUD50 — Secure3 Control 21 Register
  [7] SCUREGSEC3A3C, [6] SCUREGSEC3A38, [5] SCUREGSEC3A34, [4] SCUREGSEC3A30, [3] SCUREGSEC3A0C, [2] SCUREGSEC3A08, [0] SCUREGSEC3A00
0xD5C SCUD5C — Secure3 Control 24 Register
  [0] SCUREGSEC3B80
0xE00 SCUE00 — Write Protection 1 Register
  [4n+3] SCUREGLOCK{n:02}C (n=4..7), [30] SCUREGLOCK078, [29] SCUREGLOCK074, [26] SCUREGLOCK068, [25] SCUREGLOCK064, [24] SCUREGLOCK060, [22] SCUREGLOCK058, [21] SCUREGLOCK054, [20] SCUREGLOCK050, [18] SCUREGLOCK048, [17] SCUREGLOCK044, [16] SCUREGLOCK040, [11] SCUREGLOCK02C, [10] SCUREGLOCK028, [9] SCUREGLOCK024, [8] SCUREGLOCK020
0xE04 SCUE04 — Write Protection 2 Register
  [28] SCUREGLOCK0F0, [22] SCUREGLOCK0E0, [21] SCUREGLOCK0D4, [20] SCUREGLOCK0D0, [19] SCUREGLOCK0CC, [18] SCUREGLOCK0C8, [17] SCUREGLOCK0C4, [16] SCUREGLOCK0C0, [15] SCUREGLOCK0BC, [12] SCUREGLOCK0B0, [11] SCUREGLOCK9AC, [10] SCUREGLOCK9A8, [9] SCUREGLOCK9A4, [7] SCUREGLOCK09C, [6] SCUREGLOCK098, [5] SCUREGLOCK094, [3] SCUREGLOCK08C, [2] SCUREGLOCK088, [1] SCUREGLOCK084
0xE08 SCUE08 — Write Protection 3 Register
  [24] SCUREGLOCK160, [23] SCUREGLOCK15C, [22] SCUREGLOCK158, [21] SCUREGLOCK154, [20] SCUREGLOCK150, [19] SCUREGLOCK14C, [18] SCUREGLOCK148, [17] SCUREGLOCK144, [16] SCUREGLOCK140, [13] SCUREGLOCK134, [12] SCUREGLOCK130, [11] SCUREGLOCK12C, [10] SCUREGLOCK128, [9] SCUREGLOCK124, [8] SCUREGLOCK120, [6] SCUREGLOCK118, [3] SCUREGLOCK10C, [2] SCUREGLOCK108, [1] SCUREGLOCK104, [0] SCUREGLOCK100
0xE0C SCUE0C — Write Protection 4 Register
  [31] SCUREGLOCK1FC, [30] SCUREGLOCK1F8, [29] SCUREGLOCK1F4, [28] SCUREGLOCK1F0, [27] SCUREGLOCK1EC, [26] SCUREGLOCK1E8, [25] SCUREGLOCK1E4, [24] SCUREGLOCK1E0, [23] SCUREGLOCK1DC, [22] SCUREGLOCK1D8, [21] SCUREGLOCK1D4, [20] SCUREGLOCK1D0, [19] SCUREGLOCK1CC, [18] SCUREGLOCK1C8, [17] SCUREGLOCK1C4, [16] SCUREGLOCK1C0, [15] SCUREGLOCK1BC, [14] SCUREGLOCK1B8, [13] SCUREGLOCK1B4, [12] SCUREGLOCK1B0, [11] SCUREGLOCK1AC, [10] SCUREGLOCK1A8, [9] SCUREGLOCK1A4, [8] SCUREGLOCK1A0, [7] SCUREGLOCK19C, [6] SCUREGLOCK198, [5] SCUREGLOCK194, [4] SCUREGLOCK190, [3] SCUREGLOCK18C, [2] SCUREGLOCK188, [1] SCUREGLOCK184, [0] SCUREGLOCK180
0xE10 SCUE10 — Write Protection 5 Register
  [31] SCUREGLOCK27C, [30] SCUREGLOCK278, [29] SCUREGLOCK274, [28] SCUREGLOCK270, [23] SCUREGLOCK25C, [22] SCUREGLOCK258, [21] SCUREGLOCK254, [20] SCUREGLOCK250, [15] SCUREGLOCK23C, [14] SCUREGLOCK238, [13] SCUREGLOCK234, [12] SCUREGLOCK230, [7] SCUREGLOCK21C, [6] SCUREGLOCK218, [5] SCUREGLOCK214, [4] SCUREGLOCK210
0xE14 SCUE14 — Write Protection 6 Register
  [30] SCUREGLOCK2F8, [29] SCUREGLOCK2F4, [28] SCUREGLOCK2F0, [15] SCUREGLOCK2BC, [14] SCUREGLOCK2B8, [13] SCUREGLOCK2B4, [12] SCUREGLOCK2B0, [11] SCUREGLOCK2AC, [10] SCUREGLOCK2A8, [9] SCUREGLOCK2A4, [8] SCUREGLOCK2A0
0xE18 SCUE18 — Write Protection 7 Register
  [21] SCUREGLOCK354, [20] SCUREGLOCK350, [17] SCUREGLOCK344, [16] SCUREGLOCK340, [13] SCUREGLOCK334, [12] SCUREGLOCK330, [9] SCUREGLOCK324, [8] SCUREGLOCK320, [7] SCUREGLOCK31C, [6] SCUREGLOCK318, [5] SCUREGLOCK314, [4] SCUREGLOCK310, [1] SCUREGLOCK304, [0] SCUREGLOCK300
0xE1C SCUE1C — Write Protection 8 Register
  [16] SCUREGLOCK3C0, [15] SCUREGLOCK3BC, [14] SCUREGLOCK3B8, [13] SCUREGLOCK3B4, [9] SCUREGLOCK3A4, [8] SCUREGLOCK3A0, [6] SCUREGLOCK398, [5] SCUREGLOCK394, [4] SCUREGLOCK390, [1] SCUREGLOCK384, [0] SCUREGLOCK380
0xE24 SCUE24 — Write Protection 10 Register
  [8] SCUREGLOCK4A0
0xE28 SCUE28 — Write Protection 11 Register
  [31] SCUREGLOCK57C, [19] SCUREGLOCK54C, [18] SCUREGLOCK548, [17] SCUREGLOCK544, [16] SCUREGLOCK540, [8] SCUREGLOCK520, [7] SCUREGLOCK51C, [6] SCUREGLOCK518, [5] SCUREGLOCK514, [4] SCUREGLOCK510, [3] SCUREGLOCK50C, [2] SCUREGLOCK508, [1] SCUREGLOCK504, [0] SCUREGLOCK500
0xE2C SCUE2C — Write Protection 12 Register
  [8] SCUREGLOCK5A0, [7] SCUREGLOCK59C, [6] SCUREGLOCK598, [5] SCUREGLOCK594, [4] SCUREGLOCK590, [3] SCUREGLOCK58C, [2] SCUREGLOCK588, [1] SCUREGLOCK584, [0] SCUREGLOCK580
0xE30 SCUE30 — Write Protection 13 Register
  [8] SCUREGLOCK620, [7] SCUREGLOCK61C, [6] SCUREGLOCK618, [5] SCUREGLOCK614, [4] SCUREGLOCK610, [3] SCUREGLOCK60C, [2] SCUREGLOCK608, [1] SCUREGLOCK604, [0] SCUREGLOCK600
0xE34 SCUE34 — Write Protection 14 Register
  [31] SCUREGLOCK6FC, [8] SCUREGLOCK6A0, [7] SCUREGLOCK69C, [6] SCUREGLOCK698, [5] SCUREGLOCK694, [4] SCUREGLOCK690, [3] SCUREGLOCK68C, [2] SCUREGLOCK688, [1] SCUREGLOCK684, [0] SCUREGLOCK680
0xE38 SCUE38 — Write Protection 15 Register
  [22] SCUREGLOCK758, [21] SCUREGLOCK754, [20] SCUREGLOCK750, [19] SCUREGLOCK74C, [18] SCUREGLOCK748, [17] SCUREGLOCK744, [16] SCUREGLOCK740, [6] SCUREGLOCK718, [5] SCUREGLOCK714, [4] SCUREGLOCK710, [3] SCUREGLOCK70C, [2] SCUREGLOCK708, [1] SCUREGLOCK704, [0] SCUREGLOCK700
0xE3C SCUE3C — Write Protection 16 Register
  [22] SCUREGLOCK7D8, [21] SCUREGLOCK7D4, [20] SCUREGLOCK7D0, [19] SCUREGLOCK7CC, [18] SCUREGLOCK7C8, [17] SCUREGLOCK7C4, [16] SCUREGLOCK7C0, [6] SCUREGLOCK798, [5] SCUREGLOCK794, [4] SCUREGLOCK790, [3] SCUREGLOCK78C, [2] SCUREGLOCK788, [1] SCUREGLOCK784, [0] SCUREGLOCK780
0xE40 SCUE40 — Write Protection 17 Register
  [4n-317] SCUREGLOCK{n}C (n=80..87), [30] SCUREGLOCK878, [29] SCUREGLOCK874, [28] SCUREGLOCK870, [26] SCUREGLOCK868, [25] SCUREGLOCK864, [24] SCUREGLOCK860, [22] SCUREGLOCK858, [21] SCUREGLOCK854, [20] SCUREGLOCK850, [18] SCUREGLOCK848, [17] SCUREGLOCK844, [16] SCUREGLOCK840, [14] SCUREGLOCK838, [13] SCUREGLOCK834, [12] SCUREGLOCK830, [10] SCUREGLOCK828, [9] SCUREGLOCK824, [8] SCUREGLOCK820, [6] SCUREGLOCK818, [5] SCUREGLOCK814, [4] SCUREGLOCK810, [2] SCUREGLOCK808, [1] SCUREGLOCK804, [0] SCUREGLOCK800
0xE44 SCUE44 — Write Protection 18 Register
  [31] SCUREGLOCK8FC, [30] SCUREGLOCK8F8, [29] SCUREGLOCK8F4, [28] SCUREGLOCK8F0, [27] SCUREGLOCK8EC, [26] SCUREGLOCK8E8, [25] SCUREGLOCK8E4, [24] SCUREGLOCK8E0, [23] SCUREGLOCK8DC, [22] SCUREGLOCK8D8, [21] SCUREGLOCK8D4, [20] SCUREGLOCK8D0, [19] SCUREGLOCK8CC, [18] SCUREGLOCK8C8, [17] SCUREGLOCK8C4, [16] SCUREGLOCK8C0, [15] SCUREGLOCK8BC, [14] SCUREGLOCK8B8, [13] SCUREGLOCK8B4, [12] SCUREGLOCK8B0, [11] SCUREGLOCK8AC, [10] SCUREGLOCK8A8, [9] SCUREGLOCK8A4, [8] SCUREGLOCK8A0, [7] SCUREGLOCK89C, [6] SCUREGLOCK898, [5] SCUREGLOCK894, [4] SCUREGLOCK890, [3] SCUREGLOCK88C, [2] SCUREGLOCK888, [1] SCUREGLOCK884, [0] SCUREGLOCK880
0xE48 SCUE48 — Write Protection 19 Register
  [27] SCUREGLOCK974, [20] SCUREGLOCK958, [19] SCUREGLOCK954, [18] SCUREGLOCK950, [17] SCUREGLOCK94C, [16] SCUREGLOCK948, [15] SCUREGLOCK944, [14] SCUREGLOCK940, [13] SCUREGLOCK934, [12] SCUREGLOCK930, [11] SCUREGLOCK92C, [10] SCUREGLOCK928, [9] SCUREGLOCK924, [8] SCUREGLOCK920, [6] SCUREGLOCK918, [5] SCUREGLOCK914, [4] SCUREGLOCK910, [3] SCUREGLOCK90C, [2] SCUREGLOCK908, [1] SCUREGLOCK904, [0] SCUREGLOCK900
0xE4C SCUE4C — Write Protection 20 Register
  [15] SCUREGLOCK9BC, [14] SCUREGLOCK9B8, [13] SCUREGLOCK9B4, [12] SCUREGLOCK9B0, [3] SCUREGLOCK98C, [2] SCUREGLOCK988, [1] SCUREGLOCK984, [0] SCUREGLOCK980
0xE50 SCUE50 — Write Protection 21 Register
  [7] SCUREGLOCKA3C, [6] SCUREGLOCKA38, [5] SCUREGLOCKA34, [4] SCUREGLOCKA30, [3] SCUREGLOCKA0C, [2] SCUREGLOCKA08, [0] SCUREGLOCKA00
0xE54 SCUE54 — Write Protection 22 Register
  [15] SCUREGLOCKABC, [14] SCUREGLOCKAB8, [13] SCUREGLOCKAB4, [12] SCUREGLOCKAB0, [11] SCUREGLOCKAAC, [10] SCUREGLOCKAA8, [9] SCUREGLOCKAA4, [8] SCUREGLOCKAA0, [7] SCUREGLOCKA9C, [6] SCUREGLOCKA98, [5] SCUREGLOCKA94, [4] SCUREGLOCKA90, [3] SCUREGLOCKA8C, [2] SCUREGLOCKA88, [1] SCUREGLOCKA84, [0] SCUREGLOCKA80
0xE5C SCUE5C — Write Protection 23 Register
  [0] SCUREGLOCKB80
0xE60 SCUE60 — Write Protection 24 Register
  [30] SCUREGLOCKC78, [27] SCUREGLOCKC6C, [26] SCUREGLOCKC68, [25] SCUREGLOCKC64, [24] SCUREGLOCKC60, [23] SCUREGLOCKC5C, [21] SCUREGLOCKC54, [20] SCUREGLOCKC50, [19] SCUREGLOCKC4C, [18] SCUREGLOCKC48, [16] SCUREGLOCKC40, [13] SCUREGLOCKC34, [10] SCUREGLOCKC28, [9] SCUREGLOCKC24, [8] SCUREGLOCKC20, [7] SCUREGLOCKC1C, [6] SCUREGLOCKC18, [5] SCUREGLOCKC14, [4] SCUREGLOCKC10, [3] SCUREGLOCKC0C, [2] SCUREGLOCKC08, [1] SCUREGLOCKC04, [0] SCUREGLOCKC00
0xE64 SCUE64 — Write Protection 26 Register
  [30] SCUREGLOCKCF8, [27] SCUREGLOCKCEC, [26] SCUREGLOCKCE8, [25] SCUREGLOCKCE4, [24] SCUREGLOCKCE0, [23] SCUREGLOCKCDC, [22] SCUREGLOCKCD8, [21] SCUREGLOCKCD4, [20] SCUREGLOCKCD0, [19] SCUREGLOCKCCC, [18] SCUREGLOCKCC8, [16] SCUREGLOCKCC0, [13] SCUREGLOCKCB4, [10] SCUREGLOCKCA8, [9] SCUREGLOCKCA4, [8] SCUREGLOCKCA0, [7] SCUREGLOCKC9C, [6] SCUREGLOCKC98, [5] SCUREGLOCKC94, [4] SCUREGLOCKC90, [3] SCUREGLOCKC8C, [2] SCUREGLOCKC88, [1] SCUREGLOCKC84, [0] SCUREGLOCKC80
0xE68 SCUE68 — Write Protection 27 Register
  [30] SCUREGLOCKD78, [27] SCUREGLOCKD6C, [26] SCUREGLOCKD68, [25] SCUREGLOCKD64, [24] SCUREGLOCKD60, [23] SCUREGLOCKD5C, [22] SCUREGLOCKD58, [21] SCUREGLOCKD54, [20] SCUREGLOCKD50, [19] SCUREGLOCKD4C, [18] SCUREGLOCKD48, [16] SCUREGLOCKD40, [13] SCUREGLOCKD34, [10] SCUREGLOCKD28, [9] SCUREGLOCKD24, [8] SCUREGLOCKD20, [7] SCUREGLOCKD1C, [6] SCUREGLOCKD18, [5] SCUREGLOCKD14, [4] SCUREGLOCKD10, [3] SCUREGLOCKD0C, [2] SCUREGLOCKD08, [1] SCUREGLOCKD04, [0] SCUREGLOCKD00
0xE70 SCUE70 — Write Protection 29 Register
  [30] SCUREGLOCKE78, [28] SCUREGLOCKE70, [26] SCUREGLOCKE68, [25] SCUREGLOCKE64, [24] SCUREGLOCKE60, [4n+3] SCUREGLOCKE{n}C (n=0..5), [21] SCUREGLOCKE54, [20] SCUREGLOCKE50, [18] SCUREGLOCKE48, [17] SCUREGLOCKE44, [16] SCUREGLOCKE40, [14] SCUREGLOCKE38, [13] SCUREGLOCKE34, [12] SCUREGLOCKE30, [10] SCUREGLOCKE28, [9] SCUREGLOCKE24, [8] SCUREGLOCKE20, [6] SCUREGLOCKE18, [5] SCUREGLOCKE14, [4] SCUREGLOCKE10, [2] SCUREGLOCKE08, [1] SCUREGLOCKE04, [0] SCUREGLOCKE00
0xE78 SCUE78 — Write Protection 31 Register
  [30] SCUREGLOCKF78, [28] SCUREGLOCKF70, [4n+3] SCUREGLOCKF{n}C (n=0..6), [26] SCUREGLOCKF68, [25] SCUREGLOCKF64, [24] SCUREGLOCKF60, [21] SCUREGLOCKF54, [20] SCUREGLOCKF50, [18] SCUREGLOCKF48, [17] SCUREGLOCKF44, [16] SCUREGLOCKF40, [14] SCUREGLOCKF38, [13] SCUREGLOCKF34, [12] SCUREGLOCKF30, [10] SCUREGLOCKF28, [9] SCUREGLOCKF24, [8] SCUREGLOCKF20, [6] SCUREGLOCKF18, [5] SCUREGLOCKF14, [4] SCUREGLOCKF10, [2] SCUREGLOCKF08, [1] SCUREGLOCKF04, [0] SCUREGLOCKF00
0xF00 SCUF00 — Reset Control 1 Register
  [4n+3] SCUREGRST{n:02}C (n=4..7), [30] SCUREGRST078, [29] SCUREGRST074, [28] SCUREGRST070, [26] SCUREGRST068, [25] SCUREGRST064, [24] SCUREGRST060, [22] SCUREGRST058, [21] SCUREGRST054, [20] SCUREGRST050, [18] SCUREGRST048, [17] SCUREGRST044, [16] SCUREGRST040, [12] SCUREGRST030, [11] SCUREGRST02C, [10] SCUREGRST028, [9] SCUREGRST024, [8] SCUREGRST020, [4] SCUREGRST010
0xF04 SCUF04 — Reset Control 2 Register
  [28] SCUREGRST0F0, [22] SCUREGRST0E0, [21] SCUREGRST0D4, [20] SCUREGRST0D0, [19] SCUREGRST0CC, [18] SCUREGRST0C8, [17] SCUREGRST0C4, [16] SCUREGRST0C0, [15] SCUREGRST0BC, [12] SCUREGRST0B0, [11] SCUREGRST9AC, [10] SCUREGRST9A8, [9] SCUREGRST9A4, [7] SCUREGRST09C, [6] SCUREGRST098, [5] SCUREGRST094, [3] SCUREGRST08C, [2] SCUREGRST088, [1] SCUREGRST084, [0] SCUREGRST080
0xF08 SCUF08 — Reset Control 3 Register
  [24] SCUREGRST160, [23] SCUREGRST15C, [22] SCUREGRST158, [21] SCUREGRST154, [20] SCUREGRST150, [19] SCUREGRST14C, [18] SCUREGRST148, [17] SCUREGRST144, [16] SCUREGRST140, [13] SCUREGRST134, [12] SCUREGRST130, [11] SCUREGRST12C, [10] SCUREGRST128, [9] SCUREGRST124, [8] SCUREGRST120, [3] SCUREGRST10C, [2] SCUREGRST108, [1] SCUREGRST104, [0] SCUREGRST100
0xF0C SCUF0C — Reset Control 4 Register
  [31] SCUREGRST1FC, [30] SCUREGRST1F8, [29] SCUREGRST1F4, [28] SCUREGRST1F0, [27] SCUREGRST1EC, [26] SCUREGRST1E8, [25] SCUREGRST1E4, [24] SCUREGRST1E0, [23] SCUREGRST1DC, [22] SCUREGRST1D8, [21] SCUREGRST1D4, [20] SCUREGRST1D0, [19] SCUREGRST1CC, [18] SCUREGRST1C8, [17] SCUREGRST1C4, [16] SCUREGRST1C0, [15] SCUREGRST1BC, [14] SCUREGRST1B8, [13] SCUREGRST1B4, [12] SCUREGRST1B0, [11] SCUREGRST1AC, [10] SCUREGRST1A8, [9] SCUREGRST1A4, [8] SCUREGRST1A0, [7] SCUREGRST19C, [6] SCUREGRST198, [5] SCUREGRST194, [4] SCUREGRST190, [3] SCUREGRST18C, [2] SCUREGRST188, [1] SCUREGRST184, [0] SCUREGRST180
0xF10 SCUF10 — Reset Control 5 Register
  [31] SCUREGRST27C, [30] SCUREGRST278, [29] SCUREGRST274, [28] SCUREGRST270, [25] SCUREGRST264, [24] SCUREGRST260, [23] SCUREGRST25C, [22] SCUREGRST258, [21] SCUREGRST254, [20] SCUREGRST250, [17] SCUREGRST244, [16] SCUREGRST240, [15] SCUREGRST23C, [14] SCUREGRST238, [13] SCUREGRST234, [12] SCUREGRST230, [9] SCUREGRST224, [8] SCUREGRST220, [7] SCUREGRST21C, [6] SCUREGRST218, [5] SCUREGRST214, [4] SCUREGRST210, [1] SCUREGRST204, [0] SCUREGRST200
0xF14 SCUF14 — Reset Control 6 Register
  [30] SCUREGRST2F8, [29] SCUREGRST2F4, [28] SCUREGRST2F0, [15] SCUREGRST2BC, [14] SCUREGRST2B8, [13] SCUREGRST2B4, [12] SCUREGRST2B0, [11] SCUREGRST2AC, [10] SCUREGRST2A8, [9] SCUREGRST2A4, [8] SCUREGRST2A0, [1] SCUREGRST284, [0] SCUREGRST280
0xF18 SCUF18 — Reset Control 7 Register
  [17] SCUREGRST344, [16] SCUREGRST340, [13] SCUREGRST334, [12] SCUREGRST330, [9] SCUREGRST324, [8] SCUREGRST320, [7] SCUREGRST31C, [6] SCUREGRST318, [5] SCUREGRST314, [4] SCUREGRST310, [1] SCUREGRST304, [0] SCUREGRST300
0xF1C SCUF1C — Reset Control 8 Register
  [16] SCUREGRST3C0, [15] SCUREGRST3BC, [14] SCUREGRST3B8, [13] SCUREGRST3B4, [12] SCUREGRST3B0, [9] SCUREGRST3A4, [8] SCUREGRST3A0, [6] SCUREGRST398, [5] SCUREGRST394, [4] SCUREGRST390, [1] SCUREGRST384, [0] SCUREGRST380
0xF20 SCUF20 — Reset Control 9 Register
  [4n-157] SCUREGRST{n}C (n=40..47), [28] SCUREGRST470, [26] SCUREGRST468, [25] SCUREGRST464, [24] SCUREGRST460, [22] SCUREGRST458, [21] SCUREGRST454, [20] SCUREGRST450, [18] SCUREGRST448, [17] SCUREGRST444, [16] SCUREGRST440, [14] SCUREGRST438, [13] SCUREGRST434, [12] SCUREGRST430, [10] SCUREGRST428, [9] SCUREGRST424, [8] SCUREGRST420, [6] SCUREGRST418, [5] SCUREGRST414, [4] SCUREGRST410, [2] SCUREGRST408, [1] SCUREGRST404, [0] SCUREGRST400
0xF24 SCUF24 — Reset Control 10 Register
  [31] SCUREGRST4FC, [30] SCUREGRST4F8, [29] SCUREGRST4F4, [28] SCUREGRST4F0, [27] SCUREGRST4EC, [26] SCUREGRST4E8, [25] SCUREGRST4E4, [24] SCUREGRST4E0, [23] SCUREGRST4DC, [22] SCUREGRST4D8, [21] SCUREGRST4D4, [20] SCUREGRST4D0, [19] SCUREGRST4CC, [18] SCUREGRST4C8, [17] SCUREGRST4C4, [16] SCUREGRST4C0, [15] SCUREGRST4BC, [14] SCUREGRST4B8, [13] SCUREGRST4B4, [12] SCUREGRST4B0, [11] SCUREGRST4AC, [10] SCUREGRST4A8, [9] SCUREGRST4A4, [8] SCUREGRST4A0, [7] SCUREGRST49C, [6] SCUREGRST498, [5] SCUREGRST494, [4] SCUREGRST490, [3] SCUREGRST48C, [2] SCUREGRST488, [1] SCUREGRST484, [0] SCUREGRST480
0xF28 SCUF28 — Reset Control 11 Register
  [4n-197] SCUREGRST{n}C (n=50..57), [30] SCUREGRST578, [29] SCUREGRST574, [28] SCUREGRST570, [26] SCUREGRST568, [25] SCUREGRST564, [24] SCUREGRST560, [22] SCUREGRST558, [21] SCUREGRST554, [20] SCUREGRST550, [18] SCUREGRST548, [17] SCUREGRST544, [16] SCUREGRST540, [14] SCUREGRST538, [13] SCUREGRST534, [12] SCUREGRST530, [10] SCUREGRST528, [9] SCUREGRST524, [8] SCUREGRST520, [6] SCUREGRST518, [5] SCUREGRST514, [4] SCUREGRST510, [2] SCUREGRST508, [1] SCUREGRST504, [0] SCUREGRST500
0xF2C SCUF2C — Reset Control 12 Register
  [31] SCUREGRST5FC, [30] SCUREGRST5F8, [29] SCUREGRST5F4, [28] SCUREGRST5F0, [27] SCUREGRST5EC, [26] SCUREGRST5E8, [25] SCUREGRST5E4, [24] SCUREGRST5E0, [23] SCUREGRST5DC, [22] SCUREGRST5D8, [21] SCUREGRST5D4, [20] SCUREGRST5D0, [19] SCUREGRST5CC, [18] SCUREGRST5C8, [17] SCUREGRST5C4, [16] SCUREGRST5C0, [15] SCUREGRST5BC, [14] SCUREGRST5B8, [13] SCUREGRST5B4, [12] SCUREGRST5B0, [11] SCUREGRST5AC, [10] SCUREGRST5A8, [9] SCUREGRST5A4, [8] SCUREGRST5A0, [7] SCUREGRST59C, [6] SCUREGRST598, [5] SCUREGRST594, [4] SCUREGRST590, [3] SCUREGRST58C, [2] SCUREGRST588, [1] SCUREGRST584, [0] SCUREGRST580
0xF30 SCUF30 — Reset Control 13 Register
  [8] SCUREGRST620, [7] SCUREGRST61C, [6] SCUREGRST618, [5] SCUREGRST614, [4] SCUREGRST610, [3] SCUREGRST60C, [2] SCUREGRST608, [1] SCUREGRST604, [0] SCUREGRST600
0xF34 SCUF34 — Reset Control 14 Register
  [31] SCUREGRST6FC, [8] SCUREGRST6A0, [7] SCUREGRST69C, [6] SCUREGRST698, [5] SCUREGRST694, [4] SCUREGRST690, [3] SCUREGRST68C, [2] SCUREGRST688, [1] SCUREGRST684, [0] SCUREGRST680
0xF38 SCUF38 — Reset Control 15 Register
  [22] SCUREGRST758, [21] SCUREGRST754, [20] SCUREGRST750, [19] SCUREGRST74C, [18] SCUREGRST748, [17] SCUREGRST744, [16] SCUREGRST740, [8] SCUREGRST720, [7] SCUREGRST71C, [6] SCUREGRST718, [5] SCUREGRST714, [4] SCUREGRST710, [3] SCUREGRST70C, [2] SCUREGRST708, [1] SCUREGRST704, [0] SCUREGRST700
0xF3C SCUF3C — Reset Control 16 Register
  [22] SCUREGRST7D8, [21] SCUREGRST7D4, [20] SCUREGRST7D0, [19] SCUREGRST7CC, [18] SCUREGRST7C8, [17] SCUREGRST7C4, [16] SCUREGRST7C0, [6] SCUREGRST798, [5] SCUREGRST794, [4] SCUREGRST790, [3] SCUREGRST78C, [2] SCUREGRST788, [1] SCUREGRST784, [0] SCUREGRST780
0xF48 SCUF48 — Reset Control 19 Register
  [27] SCUREGRST974, [20] SCUREGRST958, [19] SCUREGRST954, [18] SCUREGRST950, [17] SCUREGRST94C, [16] SCUREGRST948, [15] SCUREGRST944, [14] SCUREGRST940, [13] SCUREGRST934, [12] SCUREGRST930, [11] SCUREGRST92C, [10] SCUREGRST928, [9] SCUREGRST924, [8] SCUREGRST920, [6] SCUREGRST918, [5] SCUREGRST914, [4] SCUREGRST910, [3] SCUREGRST90C, [2] SCUREGRST908, [1] SCUREGRST904, [0] SCUREGRST900
0xF4C SCUF4C — Reset Control 20 Register
  [31] SCUREGRST9FC, [15] SCUREGRST9BC, [14] SCUREGRST9B8, [13] SCUREGRST9B4, [12] SCUREGRST9B0, [3] SCUREGRST98C, [2] SCUREGRST988, [1] SCUREGRST984, [0] SCUREGRST980
0xF50 SCUF50 — Reset Control 21 Register
  [7] SCUREGRSTA3C, [6] SCUREGRSTA38, [5] SCUREGRSTA34, [4] SCUREGRSTA30, [3] SCUREGRSTA0C, [2] SCUREGRSTA08, [0] SCUREGRSTA00
0xF5C SCUF5C — Reset Control 24 Register
  [0] SCUREGRSTB80
0xF60 SCUF60 — Reset Control 25 Register
  [30] SCUREGRSTC78, [29] SCUREGRSTC74, [28] SCUREGRSTC70, [27] SCUREGRSTC6C, [26] SCUREGRSTC68, [25] SCUREGRSTC64, [24] SCUREGRSTC60, [23] SCUREGRSTC5C, [21] SCUREGRSTC54, [20] SCUREGRSTC50, [19] SCUREGRSTC4C, [18] SCUREGRSTC48, [16] SCUREGRSTC40, [13] SCUREGRSTC34, [10] SCUREGRSTC28, [9] SCUREGRSTC24, [8] SCUREGRSTC20, [7] SCUREGRSTC1C, [6] SCUREGRSTC18, [5] SCUREGRSTC14, [4] SCUREGRSTC10, [3] SCUREGRSTC0C, [2] SCUREGRSTC08, [1] SCUREGRSTC04, [0] SCUREGRSTC00
0xF64 SCUF64 — Reset Control 26 Register
  [30] SCUREGRSTCF8, [28] SCUREGRSTCF0, [27] SCUREGRSTCEC, [26] SCUREGRSTCE8, [25] SCUREGRSTCE4, [24] SCUREGRSTCE0, [23] SCUREGRSTCDC, [22] SCUREGRSTCD8, [21] SCUREGRSTCD4, [20] SCUREGRSTCD0, [19] SCUREGRSTCCC, [18] SCUREGRSTCC8, [16] SCUREGRSTCC0, [15] SCUREGRSTCBC, [14] SCUREGRSTCB8, [13] SCUREGRSTCB4, [12] SCUREGRSTCB0, [11] SCUREGRSTCAC, [10] SCUREGRSTCA8, [9] SCUREGRSTCA4, [8] SCUREGRSTCA0, [7] SCUREGRSTC9C, [6] SCUREGRSTC98, [5] SCUREGRSTC94, [4] SCUREGRSTC90, [3] SCUREGRSTC8C, [2] SCUREGRSTC88, [1] SCUREGRSTC84, [0] SCUREGRSTC80
0xF68 SCUF68 — Reset Control 27 Register
  [30] SCUREGRSTD78, [28] SCUREGRSTD70, [27] SCUREGRSTD6C, [26] SCUREGRSTD68, [25] SCUREGRSTD64, [24] SCUREGRSTD60, [23] SCUREGRSTD5C, [22] SCUREGRSTD58, [21] SCUREGRSTD54, [20] SCUREGRSTD50, [19] SCUREGRSTD4C, [18] SCUREGRSTD48, [16] SCUREGRSTD40, [13] SCUREGRSTD34, [10] SCUREGRSTD28, [9] SCUREGRSTD24, [8] SCUREGRSTD20, [7] SCUREGRSTD1C, [6] SCUREGRSTD18, [5] SCUREGRSTD14, [4] SCUREGRSTD10, [3] SCUREGRSTD0C, [2] SCUREGRSTD08, [1] SCUREGRSTD04, [0] SCUREGRSTD00
0xF6C SCUF6C — Reset Control 28 Register
  [18] SCUREGRSTDC8, [17] SCUREGRSTDC4
0xF70 SCUF70 — Reset Control 29 Register
  [30] SCUREGRSTE78, [28] SCUREGRSTE70, [4n+3] SCUREGRSTE{n}C (n=0..6), [26] SCUREGRSTE68, [25] SCUREGRSTE64, [24] SCUREGRSTE60, [22] SCUREGRSTE58, [21] SCUREGRSTE54, [20] SCUREGRSTE50, [18] SCUREGRSTE48, [17] SCUREGRSTE44, [16] SCUREGRSTE40, [14] SCUREGRSTE38, [13] SCUREGRSTE34, [12] SCUREGRSTE30, [10] SCUREGRSTE28, [9] SCUREGRSTE24, [8] SCUREGRSTE20, [6] SCUREGRSTE18, [5] SCUREGRSTE14, [4] SCUREGRSTE10, [2] SCUREGRSTE08, [1] SCUREGRSTE04, [0] SCUREGRSTE00
0xF78 SCUF78 — Reset Control 31 Register
  [31] SCUREGRSTF7C, [30] SCUREGRSTF78, [28] SCUREGRSTF70, [27] SCUREGRSTF6C, [26] SCUREGRSTF68, [25] SCUREGRSTF64, [24] SCUREGRSTF60, [22] SCUREGRSTF58, [20] SCUREGRSTF50, [19] SCUREGRSTF4C, [18] SCUREGRSTF48, [17] SCUREGRSTF44, [16] SCUREGRSTF40, [14] SCUREGRSTF38, [12] SCUREGRSTF30, [10] SCUREGRSTF28, [9] SCUREGRSTF24, [8] SCUREGRSTF20, [7] SCUREGRSTF1C, [6] SCUREGRSTF18, [5] SCUREGRSTF14, [4] SCUREGRSTF10, [3] SCUREGRSTF0C, [2] SCUREGRSTF08, [1] SCUREGRSTF04, [0] SCUREGRSTF00
